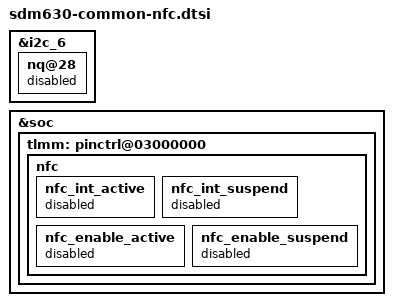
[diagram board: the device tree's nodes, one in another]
/*
 * This software is contributed or developed by KYOCERA Corporation.
 * (C) 2018 KYOCERA Corporation
 *
 * This program is free software; you can redistribute it and/or modify
 * it under the terms of the GNU General Public License version 2 and
 * only version 2 as published by the Free Software Foundation.
 *
 * This program is distributed in the hope that it will be useful,
 * but WITHOUT ANY WARRANTY; without even the implied warranty of
 * MERCHANTABILITY or FITNESS FOR A PARTICULAR PURPOSE.  See the
 * GNU General Public License for more details.
 */

&i2c_6 {
	nq@28 {
		status = "disabled";
	};
};

&soc {
	tlmm: pinctrl@03000000 {
		nfc {
			nfc_int_active: nfc_int_active {
				status = "disabled";
			};

			nfc_int_suspend: nfc_int_suspend {
				status = "disabled";
			};

			nfc_enable_active: nfc_enable_active {
				status = "disabled";
			};

			nfc_enable_suspend: nfc_enable_suspend {
				status = "disabled";
			};
		};
	};
};
